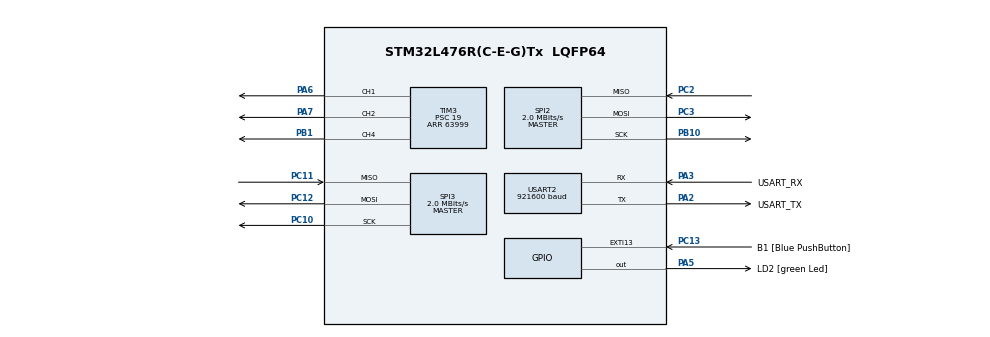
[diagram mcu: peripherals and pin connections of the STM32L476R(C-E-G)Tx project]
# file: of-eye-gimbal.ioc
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Mcu.Family=STM32L4
Mcu.Name=STM32L476R(C-E-G)Tx
Mcu.Package=LQFP64
NVIC.PriorityGroup=NVIC_PRIORITYGROUP_4
PA13\ (JTMS-SWDIO).GPIO_Label=TMS
PA13\ (JTMS-SWDIO).Mode=Serial_Wire
PA13\ (JTMS-SWDIO).Signal=SYS_JTMS-SWDIO
PA14\ (JTCK-SWCLK).GPIO_Label=TCK
PA14\ (JTCK-SWCLK).Mode=Serial_Wire
PA14\ (JTCK-SWCLK).Signal=SYS_JTCK-SWCLK
PA2.GPIO_Label=USART_TX
PA2.GPIO_Mode=GPIO_MODE_AF_PP
PA2.GPIO_PuPd=GPIO_NOPULL
PA2.GPIO_Speed=GPIO_SPEED_FREQ_VERY_HIGH
PA2.Mode=Asynchronous
PA2.Signal=USART2_TX
PA3.GPIO_Label=USART_RX
PA3.GPIO_Mode=GPIO_MODE_AF_PP
PA3.GPIO_PuPd=GPIO_NOPULL
PA3.GPIO_Speed=GPIO_SPEED_FREQ_VERY_HIGH
PA3.Mode=Asynchronous
PA3.Signal=USART2_RX
PA5.GPIO_Label=LD2 [green Led]
PA5.GPIO_ModeDefaultOutputPP=GPIO_MODE_OUTPUT_PP
PA5.GPIO_PuPd=GPIO_NOPULL
PA5.GPIO_Speed=GPIO_SPEED_FREQ_LOW
PA5.Signal=GPIO_Output
PA6.Signal=S_TIM3_CH1
PA7.Signal=S_TIM3_CH2
PB1.Signal=S_TIM3_CH4
PB10.Mode=Full_Duplex_Master
PB10.Signal=SPI2_SCK
PB3\ (JTDO-TRACESWO).GPIO_Label=SWO
PB3\ (JTDO-TRACESWO).Signal=SYS_JTDO-SWO
PC10.Mode=Full_Duplex_Master
PC10.Signal=SPI3_SCK
PC11.Mode=Full_Duplex_Master
PC11.Signal=SPI3_MISO
PC12.Mode=Full_Duplex_Master
PC12.Signal=SPI3_MOSI
PC13.GPIO_Label=B1 [Blue PushButton]
PC13.GPIO_ModeDefaultEXTI=GPIO_MODE_IT_FALLING
PC13.GPIO_PuPd=GPIO_NOPULL
PC13.Signal=GPXTI13
PC14-OSC32_IN\ (PC14).Mode=LSE-External-Oscillator
PC14-OSC32_IN\ (PC14).Signal=RCC_OSC32_IN
PC15-OSC32_OUT\ (PC15).Mode=LSE-External-Oscillator
PC15-OSC32_OUT\ (PC15).Signal=RCC_OSC32_OUT
PC2.Mode=Full_Duplex_Master
PC2.Signal=SPI2_MISO
PC3.Mode=Full_Duplex_Master
PC3.Signal=SPI2_MOSI
PH0-OSC_IN\ (PH0).Signal=RCC_OSC_IN
PH1-OSC_OUT\ (PH1).Signal=RCC_OSC_OUT
ProjectManager.HeapSize=0x200
ProjectManager.StackSize=0x400
ProjectManager.TargetToolchain=STM32CubeIDE
RCC.ADCFreq_Value=64000000
RCC.AHBFreq_Value=64000000
RCC.APB1Freq_Value=64000000
RCC.APB1TimFreq_Value=64000000
RCC.APB2Freq_Value=64000000
RCC.APB2TimFreq_Value=64000000
RCC.CortexFreq_Value=64000000
RCC.HCLKFreq_Value=64000000
RCC.HSE_VALUE=8000000
RCC.HSI_VALUE=16000000
RCC.MSI_VALUE=4000000
RCC.PLLSourceVirtual=RCC_PLLSOURCE_HSI
RCC.PREFETCH_ENABLE=1
RCC.SYSCLKFreq_VALUE=64000000
RCC.SYSCLKSource=RCC_SYSCLKSOURCE_PLLCLK
RCC.USBFreq_Value=64000000
RCC.VCOOutputFreq_Value=128000000
SH.S_TIM3_CH1.0=TIM3_CH1,PWM Generation1 CH1
SH.S_TIM3_CH2.0=TIM3_CH2,PWM Generation2 CH2
SH.S_TIM3_CH4.0=TIM3_CH4,PWM Generation4 CH4
SPI2.BaudRatePrescaler=SPI_BAUDRATEPRESCALER_32
SPI2.CLKPhase=SPI_PHASE_2EDGE
SPI2.CLKPolarity=SPI_POLARITY_HIGH
SPI2.CalculateBaudRate=2.0 MBits/s
SPI2.DataSize=SPI_DATASIZE_8BIT
SPI2.Direction=SPI_DIRECTION_2LINES
SPI2.Mode=SPI_MODE_MASTER
SPI2.VirtualType=VM_MASTER
SPI3.BaudRatePrescaler=SPI_BAUDRATEPRESCALER_32
SPI3.CLKPhase=SPI_PHASE_2EDGE
SPI3.CLKPolarity=SPI_POLARITY_HIGH
SPI3.CalculateBaudRate=2.0 MBits/s
SPI3.DataSize=SPI_DATASIZE_8BIT
SPI3.Direction=SPI_DIRECTION_2LINES
SPI3.Mode=SPI_MODE_MASTER
SPI3.VirtualType=VM_MASTER
TIM1.Period=400
TIM1.Prescaler=15
TIM3.Channel-PWM\ Generation1\ CH1=TIM_CHANNEL_1
TIM3.Channel-PWM\ Generation2\ CH2=TIM_CHANNEL_2
TIM3.Channel-PWM\ Generation4\ CH4=TIM_CHANNEL_4
TIM3.Period=63999
TIM3.Prescaler=19
TIM3.Pulse-PWM\ Generation1\ CH1=4799
TIM3.Pulse-PWM\ Generation2\ CH2=4799
TIM3.Pulse-PWM\ Generation4\ CH4=4799
TIM4.Prescaler=63999
USART2.BaudRate=921600
USART2.OverSampling=UART_OVERSAMPLING_8
USART2.VirtualMode-Asynchronous=VM_ASYNC
VP_TIM1_VS_ClockSourceINT.Mode=Internal
VP_TIM3_VS_ClockSourceINT.Mode=Internal
VP_TIM4_VS_ClockSourceINT.Mode=Internal
board=NUCLEO-L476RG

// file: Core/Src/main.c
/* USER CODE BEGIN Header */
/**
  ******************************************************************************
  * @file           : main.c
  * @brief          : Main program body
  ******************************************************************************
  * @attention
  *
  * <h2><center>&copy; Copyright (c) 2020 STMicroelectronics.
  * All rights reserved.</center></h2>
  *
  * This software component is licensed by ST under BSD 3-Clause license,
  * the "License"; You may not use this file except in compliance with the
  * License. You may obtain a copy of the License at:
  *                        opensource.org/licenses/BSD-3-Clause
  *
  ******************************************************************************
  */
/* USER CODE END Header */
#include "main.h"
#include "spi.h"
#include "tim.h"
#include "usart.h"
#include "gpio.h"

/* USER CODE BEGIN Includes */
#include "eyes.h"
#include "gimbalControl.h"
/* USER CODE END Includes */

void SystemClock_Config(void);

int main(void)
{

  /* MCU Configuration--------------------------------------------------------*/

  /* Reset of all peripherals, Initializes the Flash interface and the Systick. */

  LL_APB2_GRP1_EnableClock(LL_APB2_GRP1_PERIPH_SYSCFG);
  LL_APB1_GRP1_EnableClock(LL_APB1_GRP1_PERIPH_PWR);

  NVIC_SetPriorityGrouping(NVIC_PRIORITYGROUP_4);

  /* System interrupt init*/

  /* Configure the system clock */
  SystemClock_Config();

  /* Initialize all configured peripherals */
  MX_GPIO_Init();
  MX_USART2_UART_Init();
  MX_SPI2_Init();
  MX_TIM1_Init();
  MX_SPI3_Init();
  MX_TIM3_Init();
  MX_TIM4_Init();
  /* USER CODE BEGIN 2 */

  startupPrint();

  gimbalControlInit();

  eyes_init();
  eyes_start();

  /* USER CODE END 2 */

  /* Infinite loop */
  while (1)
  {

  }
}

void SystemClock_Config(void)
{
  LL_FLASH_SetLatency(LL_FLASH_LATENCY_3);
  while(LL_FLASH_GetLatency()!= LL_FLASH_LATENCY_3)
  {
  }
  LL_PWR_SetRegulVoltageScaling(LL_PWR_REGU_VOLTAGE_SCALE1);
  LL_RCC_HSI_Enable();

   /* Wait till HSI is ready */
  while(LL_RCC_HSI_IsReady() != 1)
  {

  }
  LL_RCC_HSI_SetCalibTrimming(16);
  LL_RCC_PLL_ConfigDomain_SYS(LL_RCC_PLLSOURCE_HSI, LL_RCC_PLLM_DIV_1, 8, LL_RCC_PLLR_DIV_2);
  LL_RCC_PLL_EnableDomain_SYS();
  LL_RCC_PLL_Enable();

   /* Wait till PLL is ready */
  while(LL_RCC_PLL_IsReady() != 1)
  {

  }
  LL_RCC_SetSysClkSource(LL_RCC_SYS_CLKSOURCE_PLL);

   /* Wait till System clock is ready */
  while(LL_RCC_GetSysClkSource() != LL_RCC_SYS_CLKSOURCE_STATUS_PLL)
  {

  }
  LL_RCC_SetAHBPrescaler(LL_RCC_SYSCLK_DIV_1);
  LL_RCC_SetAPB1Prescaler(LL_RCC_APB1_DIV_1);
  LL_RCC_SetAPB2Prescaler(LL_RCC_APB2_DIV_1);

  LL_Init1msTick(64000000);

  LL_SetSystemCoreClock(64000000);
  LL_RCC_SetUSARTClockSource(LL_RCC_USART2_CLKSOURCE_PCLK1);
}

void Error_Handler(void)
{
}

/************************ (C) COPYRIGHT STMicroelectronics *****END OF FILE****/
